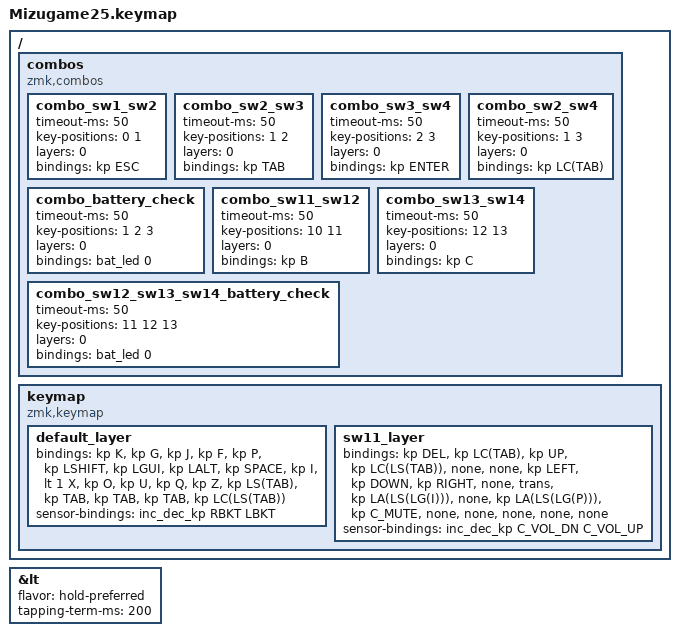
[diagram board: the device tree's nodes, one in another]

/*
 * Mizugame25
 *
 * Physical layout:
 *
 *   SW1    SW2    SW3    SW4    SW5
 *   SW6    SW7    SW8    SW9    SW10
 *   SW11   SW12   SW13   SW14   RE1
 *   ADSW1  ADSW2  ADSW3  ADSW4  ADSW5
 */

#include <behaviors.dtsi>
#include <dt-bindings/zmk/keys.h>

/*
 * SW11:
 * tap  = X
 * hold = Layer 1
 *
 * hold-preferred にして、
 * SW11を押しながら別キーを押したとき
 * レイヤー側を優先する。
 */
&lt {
    flavor = "hold-preferred";
    tapping-term-ms = <200>;
};

/ {
    combos {
        compatible = "zmk,combos";

        /* SW1 + SW2 = Esc */
        combo_sw1_sw2 {
            timeout-ms = <50>;
            key-positions = <0 1>;
            layers = <0>;
            bindings = <&kp ESC>;
        };

        /* SW2 + SW3 = Tab */
        combo_sw2_sw3 {
            timeout-ms = <50>;
            key-positions = <1 2>;
            layers = <0>;
            bindings = <&kp TAB>;
        };

        /* SW3 + SW4 = Enter */
        combo_sw3_sw4 {
            timeout-ms = <50>;
            key-positions = <2 3>;
            layers = <0>;
            bindings = <&kp ENTER>;
        };

        /* SW2 + SW4 = Ctrl + Tab */
        combo_sw2_sw4 {
            timeout-ms = <50>;
            key-positions = <1 3>;
            layers = <0>;
            bindings = <&kp LC(TAB)>;
        };

        /* SW2 + SW3 + SW4 = Battery check */
        combo_battery_check {
            timeout-ms = <50>;
            key-positions = <1 2 3>;
            layers = <0>;
            bindings = <&bat_led 0>;
        };

        /* SW11 + SW12 = B */
        combo_sw11_sw12 {
            timeout-ms = <50>;
            key-positions = <10 11>;
            layers = <0>;
            bindings = <&kp B>;
        };

        /* SW13 + SW14 = C */
        combo_sw13_sw14 {
            timeout-ms = <50>;
            key-positions = <12 13>;
            layers = <0>;
            bindings = <&kp C>;
        };

        /* SW12 + SW13 + SW14 = Battery check */
        combo_sw12_sw13_sw14_battery_check {
            timeout-ms = <50>;
            key-positions = <11 12 13>;
            layers = <0>;
            bindings = <&bat_led 0>;
        };
    };

    keymap {
        compatible = "zmk,keymap";

        /* =========================================================
         * Layer 0 : Default
         * ========================================================= */
        default_layer {
            bindings = <
                /* SW1 - SW5 */
                &kp K
                &kp G
                &kp J
                &kp F
                &kp P

                /* SW6 - SW10 */
                &kp LSHIFT
                &kp LGUI
                &kp LALT
                &kp SPACE
                &kp I

                /* SW11 - SW14 + RE1 */
                &lt 1 X
                &kp O
                &kp U
                &kp Q
                &kp Z

                /* ADSW1 - ADSW5 */
                &kp LS(TAB)
                &kp TAB
                &kp TAB
                &kp TAB
                &kp LC(LS(TAB))
            >;

            /*
             * 通常レイヤー
             * clockwise         = ]
             * counter-clockwise = [
             */
            sensor-bindings = <&inc_dec_kp RBKT LBKT>;
        };

        /* =========================================================
         * Layer 1 : SW11 Hold
         *
         * SW1  = Delete
         * SW2  = Ctrl + Tab
         * SW3  = Up
         * SW4  = Ctrl + Shift + Tab
         * SW7  = Left
         * SW8  = Down
         * SW9  = Right
         * SW12 = Alt + Shift + GUI + I
         * SW14 = Alt + Shift + GUI + P
         * RE1  = Mute
         *
         * 他は無効
         * ========================================================= */
        sw11_layer {
            bindings = <
                /* SW1 - SW5 */
                &kp DEL
                &kp LC(TAB)
                &kp UP
                &kp LC(LS(TAB))
                &none

                /* SW6 - SW10 */
                &none
                &kp LEFT
                &kp DOWN
                &kp RIGHT
                &none

                /* SW11 - SW14 + RE1 */
                &trans
                &kp LA(LS(LG(I)))
                &none
                &kp LA(LS(LG(P)))
                &kp C_MUTE

                /* ADSW1 - ADSW5 */
                &none
                &none
                &none
                &none
                &none
            >;

            /*
             * Layer 1 encoder:
             * clockwise         = Volume Up
             * counter-clockwise = Volume Down
             */
            sensor-bindings = <&inc_dec_kp C_VOL_DN C_VOL_UP>;
        };
    };
};
